# MSS_CTRL_MSS_CTRL_50D00000h register map
Vendor: Texas Instruments
Registers are 32-bit, read-only, reset values left out (the file's numbers can be read two ways) unless marked. A register's access mark holds for its fields unless they carry their own. Offsets are as the file gives them; [hi:lo] are bit positions; {n}, {i} and the like mark numbered series.

## MSS_CTRL (part 4 of 10)
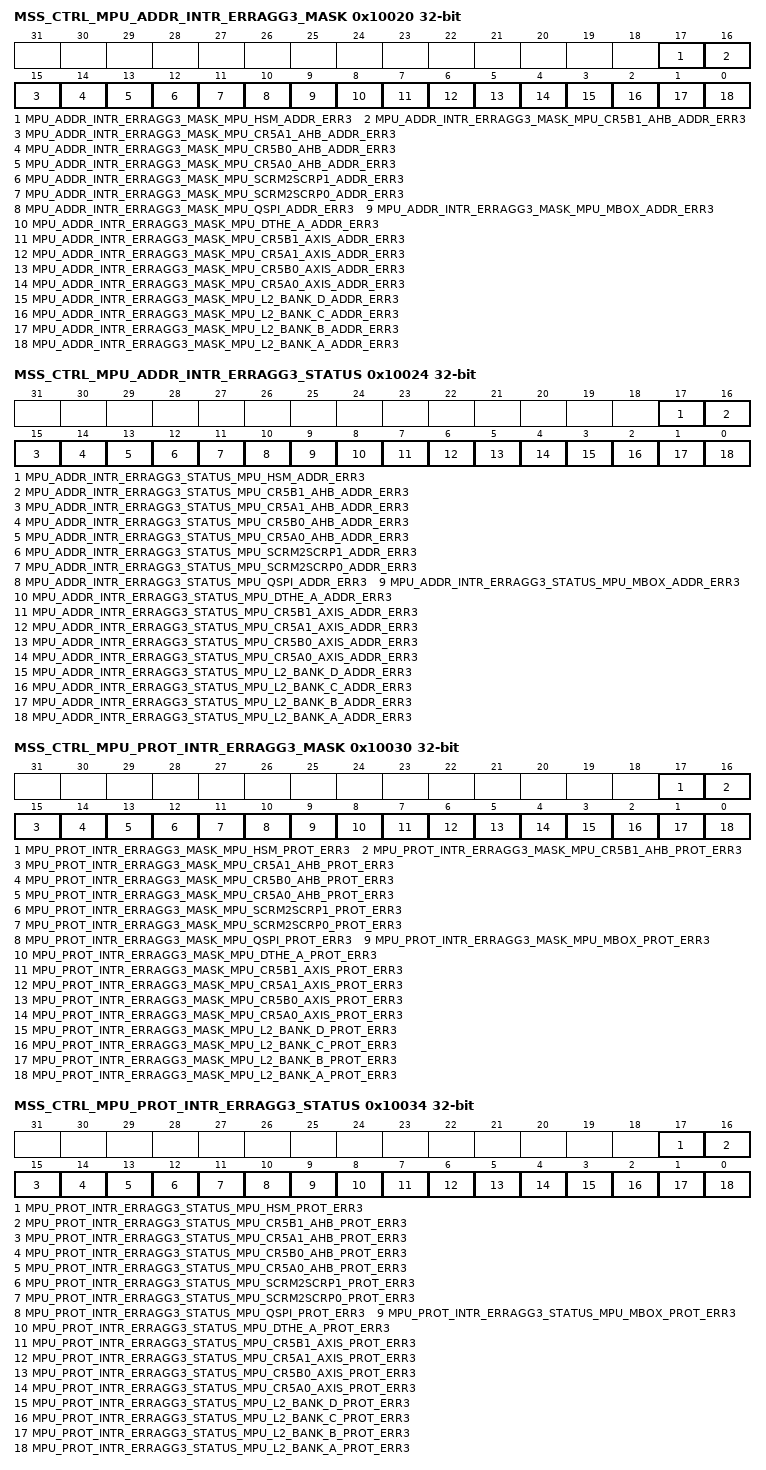
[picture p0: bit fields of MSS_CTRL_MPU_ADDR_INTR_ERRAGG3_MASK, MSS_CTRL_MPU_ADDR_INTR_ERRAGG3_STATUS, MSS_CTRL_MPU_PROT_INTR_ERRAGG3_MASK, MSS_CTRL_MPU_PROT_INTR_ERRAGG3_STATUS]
0x10020 MSS_CTRL_MPU_ADDR_INTR_ERRAGG3_MASK rw — This register Masks selected interrupt soures from generating MPU Address Error Interrupt to R5SS1 CORE1 .
  [17] MPU_ADDR_INTR_ERRAGG3_MASK_MPU_HSM_ADDR_ERR3 — Mask Error from MPU_ADDR_INTR to aggregated Error MPU_ADDR_INTR_ERRAGG1'b1 : Error is Masked1'b0 : Error is Unmasked
  [16] MPU_ADDR_INTR_ERRAGG3_MASK_MPU_CR5B1_AHB_ADDR_ERR3 — Mask Error from MPU_ADDR_INTR to aggregated Error MPU_ADDR_INTR_ERRAGG1'b1 : Error is Masked1'b0 : Error is Unmasked
  [15] MPU_ADDR_INTR_ERRAGG3_MASK_MPU_CR5A1_AHB_ADDR_ERR3 — Mask Error from MPU_ADDR_INTR to aggregated Error MPU_ADDR_INTR_ERRAGG1'b1 : Error is Masked1'b0 : Error is Unmasked
  [14] MPU_ADDR_INTR_ERRAGG3_MASK_MPU_CR5B0_AHB_ADDR_ERR3 — Mask Error from MPU_ADDR_INTR to aggregated Error MPU_ADDR_INTR_ERRAGG1'b1 : Error is Masked1'b0 : Error is Unmasked
  [13] MPU_ADDR_INTR_ERRAGG3_MASK_MPU_CR5A0_AHB_ADDR_ERR3 — Mask Error from MPU_ADDR_INTR to aggregated Error MPU_ADDR_INTR_ERRAGG1'b1 : Error is Masked1'b0 : Error is Unmasked
  [12] MPU_ADDR_INTR_ERRAGG3_MASK_MPU_SCRM2SCRP1_ADDR_ERR3 — Mask Error from MPU_ADDR_INTR to aggregated Error MPU_ADDR_INTR_ERRAGG1'b1 : Error is Masked1'b0 : Error is Unmasked
  [11] MPU_ADDR_INTR_ERRAGG3_MASK_MPU_SCRM2SCRP0_ADDR_ERR3 — Mask Error from MPU_ADDR_INTR to aggregated Error MPU_ADDR_INTR_ERRAGG1'b1 : Error is Masked1'b0 : Error is Unmasked
  [10] MPU_ADDR_INTR_ERRAGG3_MASK_MPU_QSPI_ADDR_ERR3 — Mask Error from MPU_ADDR_INTR to aggregated Error MPU_ADDR_INTR_ERRAGG1'b1 : Error is Masked1'b0 : Error is Unmasked
  [9] MPU_ADDR_INTR_ERRAGG3_MASK_MPU_MBOX_ADDR_ERR3 — Mask Error from MPU_ADDR_INTR to aggregated Error MPU_ADDR_INTR_ERRAGG1'b1 : Error is Masked1'b0 : Error is Unmasked
  [8] MPU_ADDR_INTR_ERRAGG3_MASK_MPU_DTHE_A_ADDR_ERR3 — Mask Error from MPU_ADDR_INTR to aggregated Error MPU_ADDR_INTR_ERRAGG1'b1 : Error is Masked1'b0 : Error is Unmasked
  [7] MPU_ADDR_INTR_ERRAGG3_MASK_MPU_CR5B1_AXIS_ADDR_ERR3 — Mask Error from MPU_ADDR_INTR to aggregated Error MPU_ADDR_INTR_ERRAGG1'b1 : Error is Masked1'b0 : Error is Unmasked
  [6] MPU_ADDR_INTR_ERRAGG3_MASK_MPU_CR5A1_AXIS_ADDR_ERR3 — Mask Error from MPU_ADDR_INTR to aggregated Error MPU_ADDR_INTR_ERRAGG1'b1 : Error is Masked1'b0 : Error is Unmasked
  [5] MPU_ADDR_INTR_ERRAGG3_MASK_MPU_CR5B0_AXIS_ADDR_ERR3 — Mask Error from MPU_ADDR_INTR to aggregated Error MPU_ADDR_INTR_ERRAGG1'b1 : Error is Masked1'b0 : Error is Unmasked
  [4] MPU_ADDR_INTR_ERRAGG3_MASK_MPU_CR5A0_AXIS_ADDR_ERR3 — Mask Error from MPU_ADDR_INTR to aggregated Error MPU_ADDR_INTR_ERRAGG1'b1 : Error is Masked1'b0 : Error is Unmasked
  [3] MPU_ADDR_INTR_ERRAGG3_MASK_MPU_L2_BANK_D_ADDR_ERR3 — Mask Error from MPU_ADDR_INTR to aggregated Error MPU_ADDR_INTR_ERRAGG1'b1 : Error is Masked1'b0 : Error is Unmasked
  [2] MPU_ADDR_INTR_ERRAGG3_MASK_MPU_L2_BANK_C_ADDR_ERR3 — Mask Error from MPU_ADDR_INTR to aggregated Error MPU_ADDR_INTR_ERRAGG1'b1 : Error is Masked1'b0 : Error is Unmasked
  [1] MPU_ADDR_INTR_ERRAGG3_MASK_MPU_L2_BANK_B_ADDR_ERR3 — Mask Error from MPU_ADDR_INTR to aggregated Error MPU_ADDR_INTR_ERRAGG1'b1 : Error is Masked1'b0 : Error is Unmasked
  [0] MPU_ADDR_INTR_ERRAGG3_MASK_MPU_L2_BANK_A_ADDR_ERR3 — Mask Error from MPU_ADDR_INTR to aggregated Error MPU_ADDR_INTR_ERRAGG1'b1 : Error is Masked1'b0 : Error is Unmasked
0x10024 MSS_CTRL_MPU_ADDR_INTR_ERRAGG3_STATUS rw — This register shows the Status of Unmasked MPU Address Errors to R5SS1 CORE1 .
  [17] MPU_ADDR_INTR_ERRAGG3_STATUS_MPU_HSM_ADDR_ERR3 — Status of Error from MPU_ADDR_INTR. Set only if Interupt is unmasked in MPU_ADDR_INTR_ERRAGG_MASKWrie 0x1 to clear this Error.
  [16] MPU_ADDR_INTR_ERRAGG3_STATUS_MPU_CR5B1_AHB_ADDR_ERR3 — Status of Error from MPU_ADDR_INTR. Set only if Interupt is unmasked in MPU_ADDR_INTR_ERRAGG_MASKWrie 0x1 to clear this Error.
  [15] MPU_ADDR_INTR_ERRAGG3_STATUS_MPU_CR5A1_AHB_ADDR_ERR3 — Status of Error from MPU_ADDR_INTR. Set only if Interupt is unmasked in MPU_ADDR_INTR_ERRAGG_MASKWrie 0x1 to clear this Error.
  [14] MPU_ADDR_INTR_ERRAGG3_STATUS_MPU_CR5B0_AHB_ADDR_ERR3 — Status of Error from MPU_ADDR_INTR. Set only if Interupt is unmasked in MPU_ADDR_INTR_ERRAGG_MASKWrie 0x1 to clear this Error.
  [13] MPU_ADDR_INTR_ERRAGG3_STATUS_MPU_CR5A0_AHB_ADDR_ERR3 — Status of Error from MPU_ADDR_INTR. Set only if Interupt is unmasked in MPU_ADDR_INTR_ERRAGG_MASKWrie 0x1 to clear this Error.
  [12] MPU_ADDR_INTR_ERRAGG3_STATUS_MPU_SCRM2SCRP1_ADDR_ERR3 — Status of Error from MPU_ADDR_INTR. Set only if Interupt is unmasked in MPU_ADDR_INTR_ERRAGG_MASKWrie 0x1 to clear this Error.
  [11] MPU_ADDR_INTR_ERRAGG3_STATUS_MPU_SCRM2SCRP0_ADDR_ERR3 — Status of Error from MPU_ADDR_INTR. Set only if Interupt is unmasked in MPU_ADDR_INTR_ERRAGG_MASKWrie 0x1 to clear this Error.
  [10] MPU_ADDR_INTR_ERRAGG3_STATUS_MPU_QSPI_ADDR_ERR3 — Status of Error from MPU_ADDR_INTR. Set only if Interupt is unmasked in MPU_ADDR_INTR_ERRAGG_MASKWrie 0x1 to clear this Error.
  [9] MPU_ADDR_INTR_ERRAGG3_STATUS_MPU_MBOX_ADDR_ERR3 — Status of Error from MPU_ADDR_INTR. Set only if Interupt is unmasked in MPU_ADDR_INTR_ERRAGG_MASKWrie 0x1 to clear this Error.
  [8] MPU_ADDR_INTR_ERRAGG3_STATUS_MPU_DTHE_A_ADDR_ERR3 — Status of Error from MPU_ADDR_INTR. Set only if Interupt is unmasked in MPU_ADDR_INTR_ERRAGG_MASKWrie 0x1 to clear this Error.
  [7] MPU_ADDR_INTR_ERRAGG3_STATUS_MPU_CR5B1_AXIS_ADDR_ERR3 — Status of Error from MPU_ADDR_INTR. Set only if Interupt is unmasked in MPU_ADDR_INTR_ERRAGG_MASKWrie 0x1 to clear this Error.
  [6] MPU_ADDR_INTR_ERRAGG3_STATUS_MPU_CR5A1_AXIS_ADDR_ERR3 — Status of Error from MPU_ADDR_INTR. Set only if Interupt is unmasked in MPU_ADDR_INTR_ERRAGG_MASKWrie 0x1 to clear this Error.
  [5] MPU_ADDR_INTR_ERRAGG3_STATUS_MPU_CR5B0_AXIS_ADDR_ERR3 — Status of Error from MPU_ADDR_INTR. Set only if Interupt is unmasked in MPU_ADDR_INTR_ERRAGG_MASKWrie 0x1 to clear this Error.
  [4] MPU_ADDR_INTR_ERRAGG3_STATUS_MPU_CR5A0_AXIS_ADDR_ERR3 — Status of Error from MPU_ADDR_INTR. Set only if Interupt is unmasked in MPU_ADDR_INTR_ERRAGG_MASKWrie 0x1 to clear this Error.
  [3] MPU_ADDR_INTR_ERRAGG3_STATUS_MPU_L2_BANK_D_ADDR_ERR3 — Status of Error from MPU_ADDR_INTR. Set only if Interupt is unmasked in MPU_ADDR_INTR_ERRAGG_MASKWrie 0x1 to clear this Error.
  [2] MPU_ADDR_INTR_ERRAGG3_STATUS_MPU_L2_BANK_C_ADDR_ERR3 — Status of Error from MPU_ADDR_INTR. Set only if Interupt is unmasked in MPU_ADDR_INTR_ERRAGG_MASKWrie 0x1 to clear this Error.
  [1] MPU_ADDR_INTR_ERRAGG3_STATUS_MPU_L2_BANK_B_ADDR_ERR3 — Status of Error from MPU_ADDR_INTR. Set only if Interupt is unmasked in MPU_ADDR_INTR_ERRAGG_MASKWrie 0x1 to clear this Error.
  [0] MPU_ADDR_INTR_ERRAGG3_STATUS_MPU_L2_BANK_A_ADDR_ERR3 — Status of Error from MPU_ADDR_INTR. Set only if Interupt is unmasked in MPU_ADDR_INTR_ERRAGG_MASKWrie 0x1 to clear this Error.
0x10030 MSS_CTRL_MPU_PROT_INTR_ERRAGG3_MASK rw — This register Masks selected interrupt soures from generating MPU Protection Error Interrupt to R5SS1 CORE1 .
  [17] MPU_PROT_INTR_ERRAGG3_MASK_MPU_HSM_PROT_ERR3 — Mask Error from MPU_PROT_INTR to aggregated Error MPU_PROT_INTR_ERRAGG1'b1 : Error is Masked1'b0 : Error is Unmasked
  [16] MPU_PROT_INTR_ERRAGG3_MASK_MPU_CR5B1_AHB_PROT_ERR3 — Mask Error from MPU_PROT_INTR to aggregated Error MPU_PROT_INTR_ERRAGG1'b1 : Error is Masked1'b0 : Error is Unmasked
  [15] MPU_PROT_INTR_ERRAGG3_MASK_MPU_CR5A1_AHB_PROT_ERR3 — Mask Error from MPU_PROT_INTR to aggregated Error MPU_PROT_INTR_ERRAGG1'b1 : Error is Masked1'b0 : Error is Unmasked
  [14] MPU_PROT_INTR_ERRAGG3_MASK_MPU_CR5B0_AHB_PROT_ERR3 — Mask Error from MPU_PROT_INTR to aggregated Error MPU_PROT_INTR_ERRAGG1'b1 : Error is Masked1'b0 : Error is Unmasked
  [13] MPU_PROT_INTR_ERRAGG3_MASK_MPU_CR5A0_AHB_PROT_ERR3 — Mask Error from MPU_PROT_INTR to aggregated Error MPU_PROT_INTR_ERRAGG1'b1 : Error is Masked1'b0 : Error is Unmasked
  [12] MPU_PROT_INTR_ERRAGG3_MASK_MPU_SCRM2SCRP1_PROT_ERR3 — Mask Error from MPU_PROT_INTR to aggregated Error MPU_PROT_INTR_ERRAGG1'b1 : Error is Masked1'b0 : Error is Unmasked
  [11] MPU_PROT_INTR_ERRAGG3_MASK_MPU_SCRM2SCRP0_PROT_ERR3 — Mask Error from MPU_PROT_INTR to aggregated Error MPU_PROT_INTR_ERRAGG1'b1 : Error is Masked1'b0 : Error is Unmasked
  [10] MPU_PROT_INTR_ERRAGG3_MASK_MPU_QSPI_PROT_ERR3 — Mask Error from MPU_PROT_INTR to aggregated Error MPU_PROT_INTR_ERRAGG1'b1 : Error is Masked1'b0 : Error is Unmasked
  [9] MPU_PROT_INTR_ERRAGG3_MASK_MPU_MBOX_PROT_ERR3 — Mask Error from MPU_PROT_INTR to aggregated Error MPU_PROT_INTR_ERRAGG1'b1 : Error is Masked1'b0 : Error is Unmasked
  [8] MPU_PROT_INTR_ERRAGG3_MASK_MPU_DTHE_A_PROT_ERR3 — Mask Error from MPU_PROT_INTR to aggregated Error MPU_PROT_INTR_ERRAGG1'b1 : Error is Masked1'b0 : Error is Unmasked
  [7] MPU_PROT_INTR_ERRAGG3_MASK_MPU_CR5B1_AXIS_PROT_ERR3 — Mask Error from MPU_PROT_INTR to aggregated Error MPU_PROT_INTR_ERRAGG1'b1 : Error is Masked1'b0 : Error is Unmasked
  [6] MPU_PROT_INTR_ERRAGG3_MASK_MPU_CR5A1_AXIS_PROT_ERR3 — Mask Error from MPU_PROT_INTR to aggregated Error MPU_PROT_INTR_ERRAGG1'b1 : Error is Masked1'b0 : Error is Unmasked
  [5] MPU_PROT_INTR_ERRAGG3_MASK_MPU_CR5B0_AXIS_PROT_ERR3 — Mask Error from MPU_PROT_INTR to aggregated Error MPU_PROT_INTR_ERRAGG1'b1 : Error is Masked1'b0 : Error is Unmasked
  [4] MPU_PROT_INTR_ERRAGG3_MASK_MPU_CR5A0_AXIS_PROT_ERR3 — Mask Error from MPU_PROT_INTR to aggregated Error MPU_PROT_INTR_ERRAGG1'b1 : Error is Masked1'b0 : Error is Unmasked
  [3] MPU_PROT_INTR_ERRAGG3_MASK_MPU_L2_BANK_D_PROT_ERR3 — Mask Error from MPU_PROT_INTR to aggregated Error MPU_PROT_INTR_ERRAGG1'b1 : Error is Masked1'b0 : Error is Unmasked
  [2] MPU_PROT_INTR_ERRAGG3_MASK_MPU_L2_BANK_C_PROT_ERR3 — Mask Error from MPU_PROT_INTR to aggregated Error MPU_PROT_INTR_ERRAGG1'b1 : Error is Masked1'b0 : Error is Unmasked
  [1] MPU_PROT_INTR_ERRAGG3_MASK_MPU_L2_BANK_B_PROT_ERR3 — Mask Error from MPU_PROT_INTR to aggregated Error MPU_PROT_INTR_ERRAGG1'b1 : Error is Masked1'b0 : Error is Unmasked
  [0] MPU_PROT_INTR_ERRAGG3_MASK_MPU_L2_BANK_A_PROT_ERR3 — Mask Error from MPU_PROT_INTR to aggregated Error MPU_PROT_INTR_ERRAGG1'b1 : Error is Masked1'b0 : Error is Unmasked
0x10034 MSS_CTRL_MPU_PROT_INTR_ERRAGG3_STATUS rw — This register shows the Status of Unmasked MPU Protection Errors to R5SS1 CORE1 .
  [17] MPU_PROT_INTR_ERRAGG3_STATUS_MPU_HSM_PROT_ERR3 — Status of Error from MPU_PROT_INTR. Set only if Interupt is unmasked in MPU_PROT_INTR_ERRAGG_MASKWrie 0x1 to clear this Error.
  [16] MPU_PROT_INTR_ERRAGG3_STATUS_MPU_CR5B1_AHB_PROT_ERR3 — Status of Error from MPU_PROT_INTR. Set only if Interupt is unmasked in MPU_PROT_INTR_ERRAGG_MASKWrie 0x1 to clear this Error.
  [15] MPU_PROT_INTR_ERRAGG3_STATUS_MPU_CR5A1_AHB_PROT_ERR3 — Status of Error from MPU_PROT_INTR. Set only if Interupt is unmasked in MPU_PROT_INTR_ERRAGG_MASKWrie 0x1 to clear this Error.
  [14] MPU_PROT_INTR_ERRAGG3_STATUS_MPU_CR5B0_AHB_PROT_ERR3 — Status of Error from MPU_PROT_INTR. Set only if Interupt is unmasked in MPU_PROT_INTR_ERRAGG_MASKWrie 0x1 to clear this Error.
  [13] MPU_PROT_INTR_ERRAGG3_STATUS_MPU_CR5A0_AHB_PROT_ERR3 — Status of Error from MPU_PROT_INTR. Set only if Interupt is unmasked in MPU_PROT_INTR_ERRAGG_MASKWrie 0x1 to clear this Error.
  [12] MPU_PROT_INTR_ERRAGG3_STATUS_MPU_SCRM2SCRP1_PROT_ERR3 — Status of Error from MPU_PROT_INTR. Set only if Interupt is unmasked in MPU_PROT_INTR_ERRAGG_MASKWrie 0x1 to clear this Error.
  [11] MPU_PROT_INTR_ERRAGG3_STATUS_MPU_SCRM2SCRP0_PROT_ERR3 — Status of Error from MPU_PROT_INTR. Set only if Interupt is unmasked in MPU_PROT_INTR_ERRAGG_MASKWrie 0x1 to clear this Error.
  [10] MPU_PROT_INTR_ERRAGG3_STATUS_MPU_QSPI_PROT_ERR3 — Status of Error from MPU_PROT_INTR. Set only if Interupt is unmasked in MPU_PROT_INTR_ERRAGG_MASKWrie 0x1 to clear this Error.
  [9] MPU_PROT_INTR_ERRAGG3_STATUS_MPU_MBOX_PROT_ERR3 — Status of Error from MPU_PROT_INTR. Set only if Interupt is unmasked in MPU_PROT_INTR_ERRAGG_MASKWrie 0x1 to clear this Error.
  [8] MPU_PROT_INTR_ERRAGG3_STATUS_MPU_DTHE_A_PROT_ERR3 — Status of Error from MPU_PROT_INTR. Set only if Interupt is unmasked in MPU_PROT_INTR_ERRAGG_MASKWrie 0x1 to clear this Error.
  [7] MPU_PROT_INTR_ERRAGG3_STATUS_MPU_CR5B1_AXIS_PROT_ERR3 — Status of Error from MPU_PROT_INTR. Set only if Interupt is unmasked in MPU_PROT_INTR_ERRAGG_MASKWrie 0x1 to clear this Error.
  [6] MPU_PROT_INTR_ERRAGG3_STATUS_MPU_CR5A1_AXIS_PROT_ERR3 — Status of Error from MPU_PROT_INTR. Set only if Interupt is unmasked in MPU_PROT_INTR_ERRAGG_MASKWrie 0x1 to clear this Error.
  [5] MPU_PROT_INTR_ERRAGG3_STATUS_MPU_CR5B0_AXIS_PROT_ERR3 — Status of Error from MPU_PROT_INTR. Set only if Interupt is unmasked in MPU_PROT_INTR_ERRAGG_MASKWrie 0x1 to clear this Error.
  [4] MPU_PROT_INTR_ERRAGG3_STATUS_MPU_CR5A0_AXIS_PROT_ERR3 — Status of Error from MPU_PROT_INTR. Set only if Interupt is unmasked in MPU_PROT_INTR_ERRAGG_MASKWrie 0x1 to clear this Error.
  [3] MPU_PROT_INTR_ERRAGG3_STATUS_MPU_L2_BANK_D_PROT_ERR3 — Status of Error from MPU_PROT_INTR. Set only if Interupt is unmasked in MPU_PROT_INTR_ERRAGG_MASKWrie 0x1 to clear this Error.
  [2] MPU_PROT_INTR_ERRAGG3_STATUS_MPU_L2_BANK_C_PROT_ERR3 — Status of Error from MPU_PROT_INTR. Set only if Interupt is unmasked in MPU_PROT_INTR_ERRAGG_MASKWrie 0x1 to clear this Error.
  [1] MPU_PROT_INTR_ERRAGG3_STATUS_MPU_L2_BANK_B_PROT_ERR3 — Status of Error from MPU_PROT_INTR. Set only if Interupt is unmasked in MPU_PROT_INTR_ERRAGG_MASKWrie 0x1 to clear this Error.
  [0] MPU_PROT_INTR_ERRAGG3_STATUS_MPU_L2_BANK_A_PROT_ERR3 — Status of Error from MPU_PROT_INTR. Set only if Interupt is unmasked in MPU_PROT_INTR_ERRAGG_MASKWrie 0x1 to clear this Error.
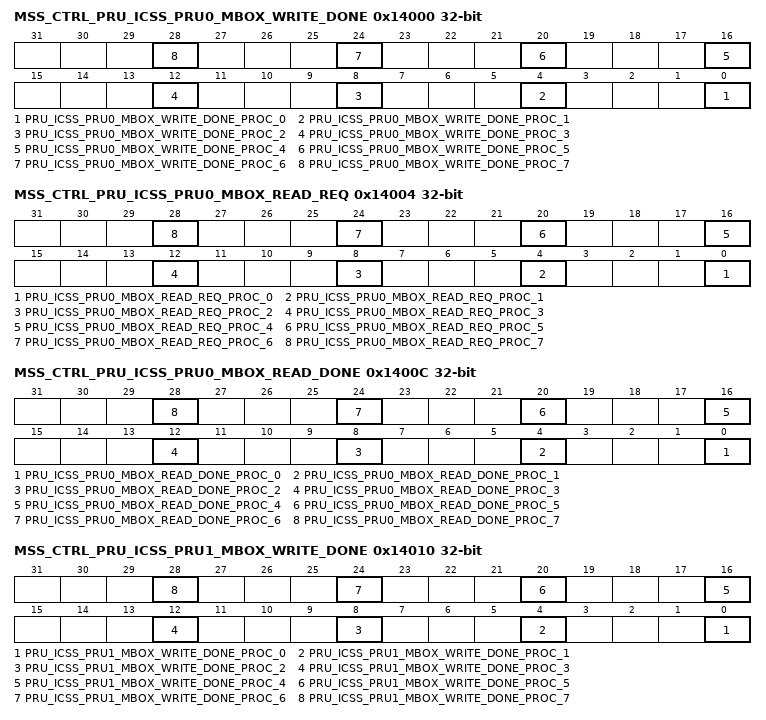
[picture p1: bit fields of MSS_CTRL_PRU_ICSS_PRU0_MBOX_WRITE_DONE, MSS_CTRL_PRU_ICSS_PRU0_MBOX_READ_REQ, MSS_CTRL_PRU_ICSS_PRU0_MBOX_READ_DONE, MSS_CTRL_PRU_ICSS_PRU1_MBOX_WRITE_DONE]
0x14000 MSS_CTRL_PRU_ICSS_PRU0_MBOX_WRITE_DONE rw — This register is used by ICSSM PRU0 to generate Mailbox interrupt to Recipent CPU.
  [4n] PRU_ICSS_PRU0_MBOX_WRITE_DONE_PROC_{n} (n=0..7) — Write pulse bit field:This register should be written once finishing Writing into the mailbox memory of processor {n}
0x14004 MSS_CTRL_PRU_ICSS_PRU0_MBOX_READ_REQ rw — This register is used by ICSSM PRU0 to know the Sender of Mailbox Interrupt as well as clear it.
  [4n] PRU_ICSS_PRU0_MBOX_READ_REQ_PROC_{n} (n=0..7) — This is request from processor {n} to corresponding ICSSM_PRU. Requesting it to read from mailbox.
0x14008 MSS_CTRL_PRU_ICSS_PRU0_MBOX_READ_DONE_ACK rw — This register is used by ICSSM PRU0 to generate Mailbox Read acknowledgement to the Sender CPU.
  [7:0] PRU_ICSS_PRU0_MBOX_READ_DONE_ACK_PROC — Write pulse bit field:For bits 0 to7:Wrting1'b1 : Generates pulse interrupt to corresponding proc from ICSSM_PRU0.For bits 8 to15:Wrting1'b1 : Generates pulse interrupt to corresponding proc from ICSSM_PRU1.
0x1400C MSS_CTRL_PRU_ICSS_PRU0_MBOX_READ_DONE rw — This register is used by ICSSM PRU0 to know that the Receiver CPU has read the Mailbox and Acked. It is also used to clear the Read Done Interrupt.
  [4n] PRU_ICSS_PRU0_MBOX_READ_DONE_PROC_{n} (n=0..7) — This register should be written once finishing Reading from corresponding proc{n}'s mailbox written by ICSSM_PRU
0x14010 MSS_CTRL_PRU_ICSS_PRU1_MBOX_WRITE_DONE rw — This register is used by ICSSM PRU1 to generate Mailbox interrupt to Recipent CPU.
  [4n] PRU_ICSS_PRU1_MBOX_WRITE_DONE_PROC_{n} (n=0..7) — Write pulse bit field:This register should be written once finishing Writing into the mailbox memory of processor {n}
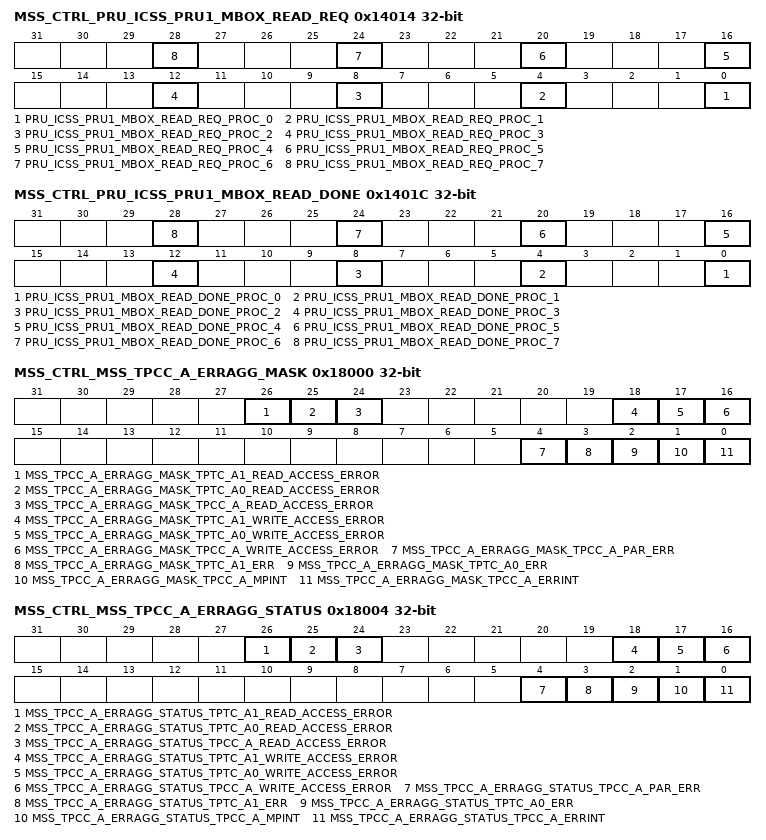
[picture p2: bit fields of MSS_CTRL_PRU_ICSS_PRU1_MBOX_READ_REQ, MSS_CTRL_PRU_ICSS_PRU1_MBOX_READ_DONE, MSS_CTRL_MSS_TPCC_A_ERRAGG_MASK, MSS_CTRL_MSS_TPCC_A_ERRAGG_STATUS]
0x14014 MSS_CTRL_PRU_ICSS_PRU1_MBOX_READ_REQ rw — This register is used by ICSSM PRU1 to know the Sender of Mailbox Interrupt as well as clear it.
  [4n] PRU_ICSS_PRU1_MBOX_READ_REQ_PROC_{n} (n=0..7) — This is request from processor {n} to corresponding ICSSM_PRU. Requesting it to read from mailbox.
0x14018 MSS_CTRL_PRU_ICSS_PRU1_MBOX_READ_DONE_ACK rw — This register is used by ICSSM PRU1 to generate Mailbox Read acknowledgement to the Sender CPU.
  [7:0] PRU_ICSS_PRU1_MBOX_READ_DONE_ACK_PROC — Write pulse bit field:For bits 0 to7:Wrting1'b1 : Generates pulse interrupt to corresponding proc from ICSSM_PRU0.For bits 8 to15:Wrting1'b1 : Generates pulse interrupt to corresponding proc from ICSSM_PRU1.
0x1401C MSS_CTRL_PRU_ICSS_PRU1_MBOX_READ_DONE rw — This register is used by ICSSM PRU1 to know that the Receiver CPU has read the Mailbox and Acked. It is also used to clear the Read Done Interrupt.
  [4n] PRU_ICSS_PRU1_MBOX_READ_DONE_PROC_{n} (n=0..7) — This register should be written once finishing Reading from corresponding proc{n}'s mailbox written by ICSSM_PRU
0x18000 MSS_CTRL_MSS_TPCC_A_ERRAGG_MASK rw — This register Masks selected interrupt soures from generating the Aggregated TPCC0 Error Interrupt.
  [26] MSS_TPCC_A_ERRAGG_MASK_TPTC_A1_READ_ACCESS_ERROR — Mask Error from MSS_TPTC_A1 to aggregated Error MSS_TPCC_A_ERRAGG1'b1 : Error is Masked1'b0 : Error is Unmasked
  [25] MSS_TPCC_A_ERRAGG_MASK_TPTC_A0_READ_ACCESS_ERROR — Mask Error from MSS_TPTC_A0 to aggregated Error MSS_TPCC_A_ERRAGG1'b1 : Error is Masked1'b0 : Error is Unmasked
  [24] MSS_TPCC_A_ERRAGG_MASK_TPCC_A_READ_ACCESS_ERROR — Mask Error from MSS_TPCC_A to aggregated Error MSS_TPCC_A_ERRAGG1'b1 : Error is Masked1'b0 : Error is Unmasked
  [18] MSS_TPCC_A_ERRAGG_MASK_TPTC_A1_WRITE_ACCESS_ERROR — Mask Error from MSS_TPTC_A1 to aggregated Error MSS_TPCC_A_ERRAGG1'b1 : Error is Masked1'b0 : Error is Unmasked
  [17] MSS_TPCC_A_ERRAGG_MASK_TPTC_A0_WRITE_ACCESS_ERROR — Mask Error from MSS_TPTC_A0 to aggregated Error MSS_TPCC_A_ERRAGG1'b1 : Error is Masked1'b0 : Error is Unmasked
  [16] MSS_TPCC_A_ERRAGG_MASK_TPCC_A_WRITE_ACCESS_ERROR — Mask Error from MSS_TPCC_A to aggregated Error MSS_TPCC_A_ERRAGG1'b1 : Error is Masked1'b0 : Error is Unmasked
  [4] MSS_TPCC_A_ERRAGG_MASK_TPCC_A_PAR_ERR — Mask Error from MSS_TPCC_A to aggregated Error MSS_TPCC_A_ERRAGG1'b1 : Error is Masked1'b0 : Error is Unmasked
  [3] MSS_TPCC_A_ERRAGG_MASK_TPTC_A1_ERR — Mask Error from MSS_TPTC_A1 to aggregated Error MSS_TPCC_A_ERRAGG1'b1 : Error is Masked1'b0 : Error is Unmasked
  [2] MSS_TPCC_A_ERRAGG_MASK_TPTC_A0_ERR — Mask Error from MSS_TPTC_A0 to aggregated Error MSS_TPCC_A_ERRAGG1'b1 : Error is Masked1'b0 : Error is Unmasked
  [1] MSS_TPCC_A_ERRAGG_MASK_TPCC_A_MPINT — Mask Error from MSS_TPCC_A to aggregated Error MSS_TPCC_A_ERRAGG1'b1 : Error is Masked1'b0 : Error is Unmasked
  [0] MSS_TPCC_A_ERRAGG_MASK_TPCC_A_ERRINT — Mask Error from MSS_TPCC_A to aggregated Error MSS_TPCC_A_ERRAGG1'b1 : Error is Masked1'b0 : Error is Unmasked
0x18004 MSS_CTRL_MSS_TPCC_A_ERRAGG_STATUS rw — This register shows the Status of Unmasked Errors from TPCC0.
  [26] MSS_TPCC_A_ERRAGG_STATUS_TPTC_A1_READ_ACCESS_ERROR — Status of Error from MSS_TPTC_A1. Set only if Interupt is unmasked in MSS_TPCC_A_ERRAGG_MASKWrie 0x1 to clear this Error.
  [25] MSS_TPCC_A_ERRAGG_STATUS_TPTC_A0_READ_ACCESS_ERROR — Status of Error from MSS_TPTC_A0. Set only if Interupt is unmasked in MSS_TPCC_A_ERRAGG_MASKWrie 0x1 to clear this Error.
  [24] MSS_TPCC_A_ERRAGG_STATUS_TPCC_A_READ_ACCESS_ERROR — Status of Error from MSS_TPCC_A. Set only if Interupt is unmasked in MSS_TPCC_A_ERRAGG_MASKWrie 0x1 to clear this Error.
  [18] MSS_TPCC_A_ERRAGG_STATUS_TPTC_A1_WRITE_ACCESS_ERROR — Status of Error from MSS_TPTC_A1. Set only if Interupt is unmasked in MSS_TPCC_A_ERRAGG_MASKWrie 0x1 to clear this Error.
  [17] MSS_TPCC_A_ERRAGG_STATUS_TPTC_A0_WRITE_ACCESS_ERROR — Status of Error from MSS_TPTC_A0. Set only if Interupt is unmasked in MSS_TPCC_A_ERRAGG_MASKWrie 0x1 to clear this Error.
  [16] MSS_TPCC_A_ERRAGG_STATUS_TPCC_A_WRITE_ACCESS_ERROR — Status of Error from MSS_TPCC_A. Set only if Interupt is unmasked in MSS_TPCC_A_ERRAGG_MASKWrie 0x1 to clear this Error.
  [4] MSS_TPCC_A_ERRAGG_STATUS_TPCC_A_PAR_ERR — Status of Error from MSS_TPCC_A. Set only if Interupt is unmasked in MSS_TPCC_A_ERRAGG_MASKWrie 0x1 to clear this Error.
  [3] MSS_TPCC_A_ERRAGG_STATUS_TPTC_A1_ERR — Status of Error from MSS_TPTC_A1. Set only if Interupt is unmasked in MSS_TPCC_A_ERRAGG_MASKWrie 0x1 to clear this Error.
  [2] MSS_TPCC_A_ERRAGG_STATUS_TPTC_A0_ERR — Status of Error from MSS_TPTC_A0. Set only if Interupt is unmasked in MSS_TPCC_A_ERRAGG_MASKWrie 0x1 to clear this Error.
  [1] MSS_TPCC_A_ERRAGG_STATUS_TPCC_A_MPINT — Status of Error from MSS_TPCC_A. Set only if Interupt is unmasked in MSS_TPCC_A_ERRAGG_MASKWrie 0x1 to clear this Error.
  [0] MSS_TPCC_A_ERRAGG_STATUS_TPCC_A_ERRINT — Status of Error from MSS_TPCC_A. Set only if Interupt is unmasked in MSS_TPCC_A_ERRAGG_MASKWrie 0x1 to clear this Error.
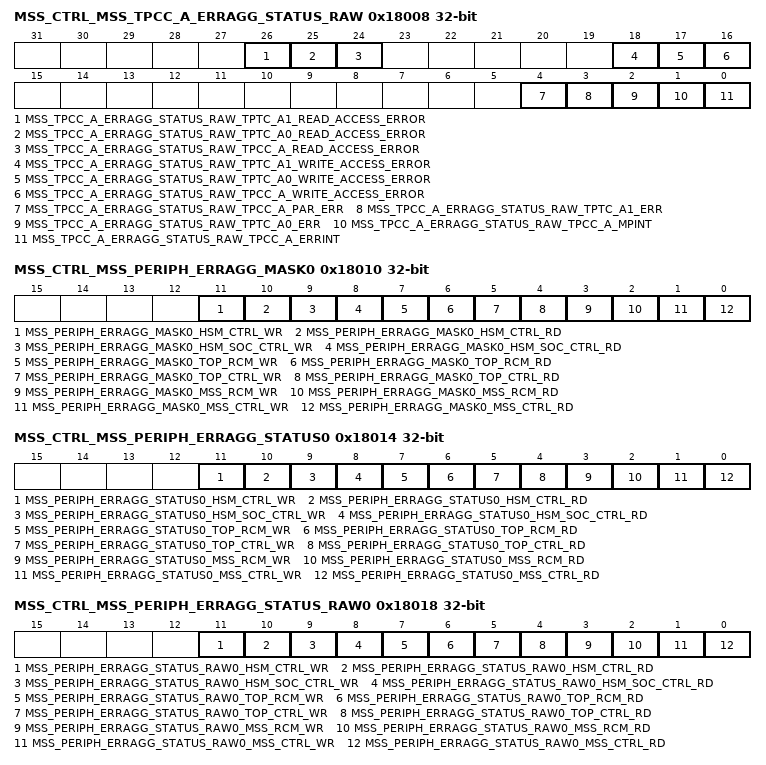
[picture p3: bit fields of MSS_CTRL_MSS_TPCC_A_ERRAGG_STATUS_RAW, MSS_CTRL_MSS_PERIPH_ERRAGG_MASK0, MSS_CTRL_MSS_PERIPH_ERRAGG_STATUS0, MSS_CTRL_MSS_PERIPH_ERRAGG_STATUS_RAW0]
0x18008 MSS_CTRL_MSS_TPCC_A_ERRAGG_STATUS_RAW rw — This register shows the Status of all Errors from TPCC0.
  [26] MSS_TPCC_A_ERRAGG_STATUS_RAW_TPTC_A1_READ_ACCESS_ERROR — Raw Status of Error from MSS_TPTC_A1. Set irrespective if the Interupt is masked or unmasked in MSS_TPCC_A_ERRAGG_MASK
  [25] MSS_TPCC_A_ERRAGG_STATUS_RAW_TPTC_A0_READ_ACCESS_ERROR — Raw Status of Error from MSS_TPTC_A0. Set irrespective if the Interupt is masked or unmasked in MSS_TPCC_A_ERRAGG_MASK
  [24] MSS_TPCC_A_ERRAGG_STATUS_RAW_TPCC_A_READ_ACCESS_ERROR — Raw Status of Error from MSS_TPCC_A. Set irrespective if the Interupt is masked or unmasked in MSS_TPCC_A_ERRAGG_MASK
  [18] MSS_TPCC_A_ERRAGG_STATUS_RAW_TPTC_A1_WRITE_ACCESS_ERROR — Raw Status of Error from MSS_TPTC_A1. Set irrespective if the Interupt is masked or unmasked in MSS_TPCC_A_ERRAGG_MASK
  [17] MSS_TPCC_A_ERRAGG_STATUS_RAW_TPTC_A0_WRITE_ACCESS_ERROR — Raw Status of Error from MSS_TPTC_A0. Set irrespective if the Interupt is masked or unmasked in MSS_TPCC_A_ERRAGG_MASK
  [16] MSS_TPCC_A_ERRAGG_STATUS_RAW_TPCC_A_WRITE_ACCESS_ERROR — Raw Status of Error from MSS_TPCC_A. Set irrespective if the Interupt is masked or unmasked in MSS_TPCC_A_ERRAGG_MASK
  [4] MSS_TPCC_A_ERRAGG_STATUS_RAW_TPCC_A_PAR_ERR — Raw Status of Error from MSS_TPCC_A. Set irrespective if the Interupt is masked or unmasked in MSS_TPCC_A_ERRAGG_MASK
  [3] MSS_TPCC_A_ERRAGG_STATUS_RAW_TPTC_A1_ERR — Raw Status of Error from MSS_TPTC_A1. Set irrespective if the Interupt is masked or unmasked in MSS_TPCC_A_ERRAGG_MASK
  [2] MSS_TPCC_A_ERRAGG_STATUS_RAW_TPTC_A0_ERR — Raw Status of Error from MSS_TPTC_A0. Set irrespective if the Interupt is masked or unmasked in MSS_TPCC_A_ERRAGG_MASK
  [1] MSS_TPCC_A_ERRAGG_STATUS_RAW_TPCC_A_MPINT — Raw Status of Error from MSS_TPCC_A. Set irrespective if the Interupt is masked or unmasked in MSS_TPCC_A_ERRAGG_MASK
  [0] MSS_TPCC_A_ERRAGG_STATUS_RAW_TPCC_A_ERRINT — Raw Status of Error from MSS_TPCC_A. Set irrespective if the Interupt is masked or unmasked in MSS_TPCC_A_ERRAGG_MASK
0x18010 MSS_CTRL_MSS_PERIPH_ERRAGG_MASK0 rw — This register Masks selected interrupt soures from generating the Aggregated MMR Access Error Interrupt.
  [11] MSS_PERIPH_ERRAGG_MASK0_HSM_CTRL_WR — Mask Interrupt from HSM_CTRL to aggregated Interrupt MSS_PERIPH_ACCESS_ERRAGG1'b1 : Interrupt is Masked1'b0 : Interrupt is Unmasked
  [10] MSS_PERIPH_ERRAGG_MASK0_HSM_CTRL_RD — Mask Interrupt from HSM_CTRL to aggregated Interrupt MSS_PERIPH_ACCESS_ERRAGG1'b1 : Interrupt is Masked1'b0 : Interrupt is Unmasked
  [9] MSS_PERIPH_ERRAGG_MASK0_HSM_SOC_CTRL_WR — Mask Interrupt from HSM_SOC_CTRL to aggregated Interrupt MSS_PERIPH_ACCESS_ERRAGG1'b1 : Interrupt is Masked1'b0 : Interrupt is Unmasked
  [8] MSS_PERIPH_ERRAGG_MASK0_HSM_SOC_CTRL_RD — Mask Interrupt from HSM_SOC_CTRL to aggregated Interrupt MSS_PERIPH_ACCESS_ERRAGG1'b1 : Interrupt is Masked1'b0 : Interrupt is Unmasked
  [7] MSS_PERIPH_ERRAGG_MASK0_TOP_RCM_WR — Mask Interrupt from TOP_RCM to aggregated Interrupt MSS_PERIPH_ACCESS_ERRAGG1'b1 : Interrupt is Masked1'b0 : Interrupt is Unmasked
  [6] MSS_PERIPH_ERRAGG_MASK0_TOP_RCM_RD — Mask Interrupt from TOP_RCM to aggregated Interrupt MSS_PERIPH_ACCESS_ERRAGG1'b1 : Interrupt is Masked1'b0 : Interrupt is Unmasked
  [5] MSS_PERIPH_ERRAGG_MASK0_TOP_CTRL_WR — Mask Interrupt from TOP_CTRL to aggregated Interrupt MSS_PERIPH_ACCESS_ERRAGG1'b1 : Interrupt is Masked1'b0 : Interrupt is Unmasked
  [4] MSS_PERIPH_ERRAGG_MASK0_TOP_CTRL_RD — Mask Interrupt from TOP_CTRL to aggregated Interrupt MSS_PERIPH_ACCESS_ERRAGG1'b1 : Interrupt is Masked1'b0 : Interrupt is Unmasked
  [3] MSS_PERIPH_ERRAGG_MASK0_MSS_RCM_WR — Mask Interrupt from MSS_RCM to aggregated Interrupt MSS_PERIPH_ACCESS_ERRAGG1'b1 : Interrupt is Masked1'b0 : Interrupt is Unmasked
  [2] MSS_PERIPH_ERRAGG_MASK0_MSS_RCM_RD — Mask Interrupt from MSS_RCM to aggregated Interrupt MSS_PERIPH_ACCESS_ERRAGG1'b1 : Interrupt is Masked1'b0 : Interrupt is Unmasked
  [1] MSS_PERIPH_ERRAGG_MASK0_MSS_CTRL_WR — Mask Interrupt from MSS_CTRL to aggregated Interrupt MSS_PERIPH_ACCESS_ERRAGG1'b1 : Interrupt is Masked1'b0 : Interrupt is Unmasked
  [0] MSS_PERIPH_ERRAGG_MASK0_MSS_CTRL_RD — Mask Interrupt from MSS_CTRL to aggregated Interrupt MSS_PERIPH_ACCESS_ERRAGG1'b1 : Interrupt is Masked1'b0 : Interrupt is Unmasked
0x18014 MSS_CTRL_MSS_PERIPH_ERRAGG_STATUS0 rw — This register shows the Status of Unmasked MMR Access Errors.
  [11] MSS_PERIPH_ERRAGG_STATUS0_HSM_CTRL_WR — Status of Interrupt from HSM_CTRLSet only if Interupt is unmasked in MSS_PERIPH_ERRAGG_MASK0Wrie 0x1 to clear this interrupt.
  [10] MSS_PERIPH_ERRAGG_STATUS0_HSM_CTRL_RD — Status of Interrupt from HSM_CTRLSet only if Interupt is unmasked in MSS_PERIPH_ERRAGG_MASK0Wrie 0x1 to clear this interrupt.
  [9] MSS_PERIPH_ERRAGG_STATUS0_HSM_SOC_CTRL_WR — Status of Interrupt from HSM_SOC_CTRLSet only if Interupt is unmasked in MSS_PERIPH_ERRAGG_MASK0Wrie 0x1 to clear this interrupt.
  [8] MSS_PERIPH_ERRAGG_STATUS0_HSM_SOC_CTRL_RD — Status of Interrupt from HSM_SOC_CTRLSet only if Interupt is unmasked in MSS_PERIPH_ERRAGG_MASK0Wrie 0x1 to clear this interrupt.
  [7] MSS_PERIPH_ERRAGG_STATUS0_TOP_RCM_WR — Status of Interrupt from TOP_RCMSet only if Interupt is unmasked in MSS_PERIPH_ERRAGG_MASK0Wrie 0x1 to clear this interrupt.
  [6] MSS_PERIPH_ERRAGG_STATUS0_TOP_RCM_RD — Status of Interrupt from TOP_RCMSet only if Interupt is unmasked in MSS_PERIPH_ERRAGG_MASK0Wrie 0x1 to clear this interrupt.
  [5] MSS_PERIPH_ERRAGG_STATUS0_TOP_CTRL_WR — Status of Interrupt from TOP_CTRLSet only if Interupt is unmasked in MSS_PERIPH_ERRAGG_MASK0Wrie 0x1 to clear this interrupt.
  [4] MSS_PERIPH_ERRAGG_STATUS0_TOP_CTRL_RD — Status of Interrupt from TOP_CTRLSet only if Interupt is unmasked in MSS_PERIPH_ERRAGG_MASK0Wrie 0x1 to clear this interrupt.
  [3] MSS_PERIPH_ERRAGG_STATUS0_MSS_RCM_WR — Status of Interrupt from MSS_RCMSet only if Interupt is unmasked in MSS_PERIPH_ERRAGG_MASK0Wrie 0x1 to clear this interrupt.
  [2] MSS_PERIPH_ERRAGG_STATUS0_MSS_RCM_RD — Status of Interrupt from MSS_RCMSet only if Interupt is unmasked in MSS_PERIPH_ERRAGG_MASK0Wrie 0x1 to clear this interrupt.
  [1] MSS_PERIPH_ERRAGG_STATUS0_MSS_CTRL_WR — Status of Interrupt from MSS_CTRLSet only if Interupt is unmasked in MSS_PERIPH_ERRAGG_MASK0Wrie 0x1 to clear this interrupt.
  [0] MSS_PERIPH_ERRAGG_STATUS0_MSS_CTRL_RD — Status of Interrupt from MSS_CTRLSet only if Interupt is unmasked in MSS_PERIPH_ERRAGG_MASK0Wrie 0x1 to clear this interrupt.
0x18018 MSS_CTRL_MSS_PERIPH_ERRAGG_STATUS_RAW0 rw — This register shows the Status of all MMR Access Errors.
  [11] MSS_PERIPH_ERRAGG_STATUS_RAW0_HSM_CTRL_WR — Raw Status of Interrupt from HSM_CTRL. Set irrespective if the Interupt is masked or unmasked in MSS_PERIPH_ERRAGG_MASK0
  [10] MSS_PERIPH_ERRAGG_STATUS_RAW0_HSM_CTRL_RD — Raw Status of Interrupt from HSM_CTRL. Set irrespective if the Interupt is masked or unmasked in MSS_PERIPH_ERRAGG_MASK0
  [9] MSS_PERIPH_ERRAGG_STATUS_RAW0_HSM_SOC_CTRL_WR — Raw Status of Interrupt from HSM_SOC_CTRL. Set irrespective if the Interupt is masked or unmasked in MSS_PERIPH_ERRAGG_MASK0
  [8] MSS_PERIPH_ERRAGG_STATUS_RAW0_HSM_SOC_CTRL_RD — Raw Status of Interrupt from HSM_SOC_CTRL. Set irrespective if the Interupt is masked or unmasked in MSS_PERIPH_ERRAGG_MASK0
  [7] MSS_PERIPH_ERRAGG_STATUS_RAW0_TOP_RCM_WR — Raw Status of Interrupt from TOP_RCM. Set irrespective if the Interupt is masked or unmasked in MSS_PERIPH_ERRAGG_MASK0
  [6] MSS_PERIPH_ERRAGG_STATUS_RAW0_TOP_RCM_RD — Raw Status of Interrupt from TOP_RCM. Set irrespective if the Interupt is masked or unmasked in MSS_PERIPH_ERRAGG_MASK0
  [5] MSS_PERIPH_ERRAGG_STATUS_RAW0_TOP_CTRL_WR — Raw Status of Interrupt from TOP_CTRL. Set irrespective if the Interupt is masked or unmasked in MSS_PERIPH_ERRAGG_MASK0
  [4] MSS_PERIPH_ERRAGG_STATUS_RAW0_TOP_CTRL_RD — Raw Status of Interrupt from TOP_CTRL. Set irrespective if the Interupt is masked or unmasked in MSS_PERIPH_ERRAGG_MASK0
  [3] MSS_PERIPH_ERRAGG_STATUS_RAW0_MSS_RCM_WR — Raw Status of Interrupt from MSS_RCM. Set irrespective if the Interupt is masked or unmasked in MSS_PERIPH_ERRAGG_MASK0
  [2] MSS_PERIPH_ERRAGG_STATUS_RAW0_MSS_RCM_RD — Raw Status of Interrupt from MSS_RCM. Set irrespective if the Interupt is masked or unmasked in MSS_PERIPH_ERRAGG_MASK0
  [1] MSS_PERIPH_ERRAGG_STATUS_RAW0_MSS_CTRL_WR — Raw Status of Interrupt from MSS_CTRL. Set irrespective if the Interupt is masked or unmasked in MSS_PERIPH_ERRAGG_MASK0
  [0] MSS_PERIPH_ERRAGG_STATUS_RAW0_MSS_CTRL_RD — Raw Status of Interrupt from MSS_CTRL. Set irrespective if the Interupt is masked or unmasked in MSS_PERIPH_ERRAGG_MASK0
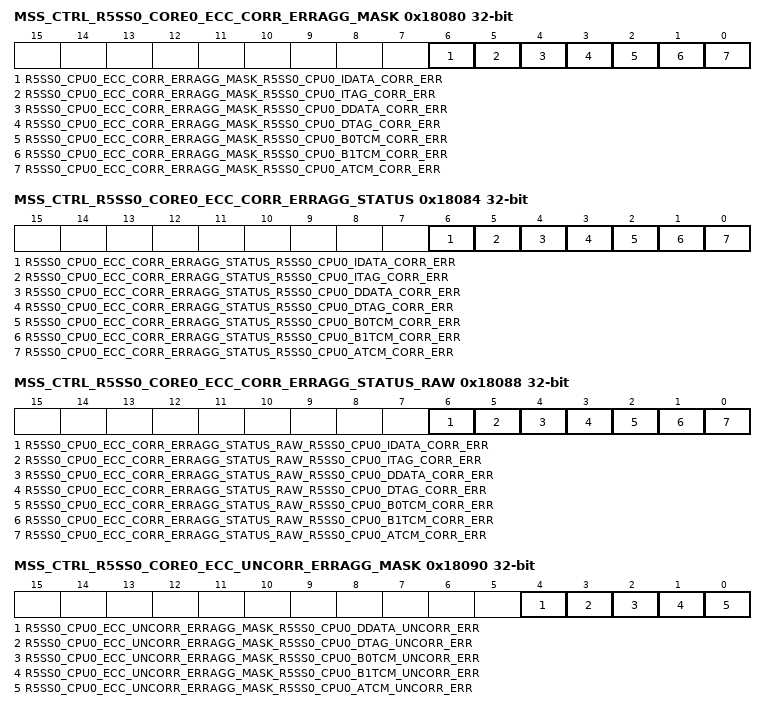
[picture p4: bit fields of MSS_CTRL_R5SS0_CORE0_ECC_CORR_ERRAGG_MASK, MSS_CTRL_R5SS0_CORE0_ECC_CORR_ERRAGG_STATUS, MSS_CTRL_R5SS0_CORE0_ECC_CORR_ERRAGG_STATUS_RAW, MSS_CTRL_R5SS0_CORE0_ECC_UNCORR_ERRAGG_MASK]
0x18080 MSS_CTRL_R5SS0_CORE0_ECC_CORR_ERRAGG_MASK rw — Register to Mask Correctable error from R5SS0 CORE0 Memories.
  [6] R5SS0_CPU0_ECC_CORR_ERRAGG_MASK_R5SS0_CPU0_IDATA_CORR_ERR — Mask Interrupt for correctable errors to aggregated Interrupt of corresponding CPU1'b1 : Interrupt is Masked1'b0 : Interrupt is Unmasked
  [5] R5SS0_CPU0_ECC_CORR_ERRAGG_MASK_R5SS0_CPU0_ITAG_CORR_ERR — Mask Interrupt for correctable errors to aggregated Interrupt of corresponding CPU1'b1 : Interrupt is Masked1'b0 : Interrupt is Unmasked
  [4] R5SS0_CPU0_ECC_CORR_ERRAGG_MASK_R5SS0_CPU0_DDATA_CORR_ERR — Mask Interrupt for correctable errors to aggregated Interrupt of corresponding CPU1'b1 : Interrupt is Masked1'b0 : Interrupt is Unmasked
  [3] R5SS0_CPU0_ECC_CORR_ERRAGG_MASK_R5SS0_CPU0_DTAG_CORR_ERR — Mask Interrupt for correctable errors to aggregated Interrupt of corresponding CPU1'b1 : Interrupt is Masked1'b0 : Interrupt is Unmasked
  [2] R5SS0_CPU0_ECC_CORR_ERRAGG_MASK_R5SS0_CPU0_B0TCM_CORR_ERR — Mask Interrupt for correctable errors to aggregated Interrupt of corresponding CPU1'b1 : Interrupt is Masked1'b0 : Interrupt is Unmasked
  [1] R5SS0_CPU0_ECC_CORR_ERRAGG_MASK_R5SS0_CPU0_B1TCM_CORR_ERR — Mask Interrupt for correctable errors to aggregated Interrupt of corresponding CPU1'b1 : Interrupt is Masked1'b0 : Interrupt is Unmasked
  [0] R5SS0_CPU0_ECC_CORR_ERRAGG_MASK_R5SS0_CPU0_ATCM_CORR_ERR — Mask Interrupt for correctable errors to aggregated Interrupt of corresponding CPU1'b1 : Interrupt is Masked1'b0 : Interrupt is Unmasked
0x18084 MSS_CTRL_R5SS0_CORE0_ECC_CORR_ERRAGG_STATUS rw — Status register based on mask for correctable error R5SS0 CORE0 Memories.
  [6] R5SS0_CPU0_ECC_CORR_ERRAGG_STATUS_R5SS0_CPU0_IDATA_CORR_ERR — Status of Interrupt from correctable error of corresponding CPUSet only if Interupt is unmasked in corresponding R5SS*_CPU*_ECC_CORR_ERRAGG_MASK registerWrie 0x1 to clear this interrupt.
  [5] R5SS0_CPU0_ECC_CORR_ERRAGG_STATUS_R5SS0_CPU0_ITAG_CORR_ERR — Status of Interrupt from correctable error of corresponding CPUSet only if Interupt is unmasked in corresponding R5SS*_CPU*_ECC_CORR_ERRAGG_MASK registerWrie 0x1 to clear this interrupt.
  [4] R5SS0_CPU0_ECC_CORR_ERRAGG_STATUS_R5SS0_CPU0_DDATA_CORR_ERR — Status of Interrupt from correctable error of corresponding CPUSet only if Interupt is unmasked in corresponding R5SS*_CPU*_ECC_CORR_ERRAGG_MASK registerWrie 0x1 to clear this interrupt.
  [3] R5SS0_CPU0_ECC_CORR_ERRAGG_STATUS_R5SS0_CPU0_DTAG_CORR_ERR — Status of Interrupt from correctable error of corresponding CPUSet only if Interupt is unmasked in corresponding R5SS*_CPU*_ECC_CORR_ERRAGG_MASK registerWrie 0x1 to clear this interrupt.
  [2] R5SS0_CPU0_ECC_CORR_ERRAGG_STATUS_R5SS0_CPU0_B0TCM_CORR_ERR — Status of Interrupt from correctable error of corresponding CPUSet only if Interupt is unmasked in corresponding R5SS*_CPU*_ECC_CORR_ERRAGG_MASK registerWrie 0x1 to clear this interrupt.
  [1] R5SS0_CPU0_ECC_CORR_ERRAGG_STATUS_R5SS0_CPU0_B1TCM_CORR_ERR — Status of Interrupt from correctable error of corresponding CPUSet only if Interupt is unmasked in corresponding R5SS*_CPU*_ECC_CORR_ERRAGG_MASK registerWrie 0x1 to clear this interrupt.
  [0] R5SS0_CPU0_ECC_CORR_ERRAGG_STATUS_R5SS0_CPU0_ATCM_CORR_ERR — Status of Interrupt from correctable error of corresponding CPUSet only if Interupt is unmasked in corresponding R5SS*_CPU*_ECC_CORR_ERRAGG_MASK registerWrie 0x1 to clear this interrupt.
0x18088 MSS_CTRL_R5SS0_CORE0_ECC_CORR_ERRAGG_STATUS_RAW rw — Raw status for correctable error from R5SS0 CORE0 Memories.
  [6] R5SS0_CPU0_ECC_CORR_ERRAGG_STATUS_RAW_R5SS0_CPU0_IDATA_CORR_ERR — Raw Status of Interrupt from correctable error of corresponding CPUSet only if Interupt is unmasked in corresponding R5SS*_CPU*_ECC_CORR_ERRAGG_MASK registerWrie 0x1 to clear this interrupt.
  [5] R5SS0_CPU0_ECC_CORR_ERRAGG_STATUS_RAW_R5SS0_CPU0_ITAG_CORR_ERR — Raw Status of Interrupt from correctable error of corresponding CPUSet only if Interupt is unmasked in corresponding R5SS*_CPU*_ECC_CORR_ERRAGG_MASK registerWrie 0x1 to clear this interrupt.
  [4] R5SS0_CPU0_ECC_CORR_ERRAGG_STATUS_RAW_R5SS0_CPU0_DDATA_CORR_ERR — Raw Status of Interrupt from correctable error of corresponding CPUSet only if Interupt is unmasked in corresponding R5SS*_CPU*_ECC_CORR_ERRAGG_MASK registerWrie 0x1 to clear this interrupt.
  [3] R5SS0_CPU0_ECC_CORR_ERRAGG_STATUS_RAW_R5SS0_CPU0_DTAG_CORR_ERR — Raw Status of Interrupt from correctable error of corresponding CPUSet only if Interupt is unmasked in corresponding R5SS*_CPU*_ECC_CORR_ERRAGG_MASK registerWrie 0x1 to clear this interrupt.
  [2] R5SS0_CPU0_ECC_CORR_ERRAGG_STATUS_RAW_R5SS0_CPU0_B0TCM_CORR_ERR — Raw Status of Interrupt from correctable error of corresponding CPUSet only if Interupt is unmasked in corresponding R5SS*_CPU*_ECC_CORR_ERRAGG_MASK registerWrie 0x1 to clear this interrupt.
  [1] R5SS0_CPU0_ECC_CORR_ERRAGG_STATUS_RAW_R5SS0_CPU0_B1TCM_CORR_ERR — Raw Status of Interrupt from correctable error of corresponding CPUSet only if Interupt is unmasked in corresponding R5SS*_CPU*_ECC_CORR_ERRAGG_MASK registerWrie 0x1 to clear this interrupt.
  [0] R5SS0_CPU0_ECC_CORR_ERRAGG_STATUS_RAW_R5SS0_CPU0_ATCM_CORR_ERR — Raw Status of Interrupt from correctable error of corresponding CPUSet only if Interupt is unmasked in corresponding R5SS*_CPU*_ECC_CORR_ERRAGG_MASK registerWrie 0x1 to clear this interrupt.
0x18090 MSS_CTRL_R5SS0_CORE0_ECC_UNCORR_ERRAGG_MASK rw — Register to Mask Uncorrectable error from R5SS0 CORE0 Memories.
  [4] R5SS0_CPU0_ECC_UNCORR_ERRAGG_MASK_R5SS0_CPU0_DDATA_UNCORR_ERR — Mask Interrupt for correctable errors to aggregated Interrupt of corresponding CPU1'b1 : Interrupt is Masked1'b0 : Interrupt is Unmasked
  [3] R5SS0_CPU0_ECC_UNCORR_ERRAGG_MASK_R5SS0_CPU0_DTAG_UNCORR_ERR — Mask Interrupt for correctable errors to aggregated Interrupt of corresponding CPU1'b1 : Interrupt is Masked1'b0 : Interrupt is Unmasked
  [2] R5SS0_CPU0_ECC_UNCORR_ERRAGG_MASK_R5SS0_CPU0_B0TCM_UNCORR_ERR — Mask Interrupt for correctable errors to aggregated Interrupt of corresponding CPU1'b1 : Interrupt is Masked1'b0 : Interrupt is Unmasked
  [1] R5SS0_CPU0_ECC_UNCORR_ERRAGG_MASK_R5SS0_CPU0_B1TCM_UNCORR_ERR — Mask Interrupt for correctable errors to aggregated Interrupt of corresponding CPU1'b1 : Interrupt is Masked1'b0 : Interrupt is Unmasked
  [0] R5SS0_CPU0_ECC_UNCORR_ERRAGG_MASK_R5SS0_CPU0_ATCM_UNCORR_ERR — Mask Interrupt for correctable errors to aggregated Interrupt of corresponding CPU1'b1 : Interrupt is Masked1'b0 : Interrupt is Unmasked
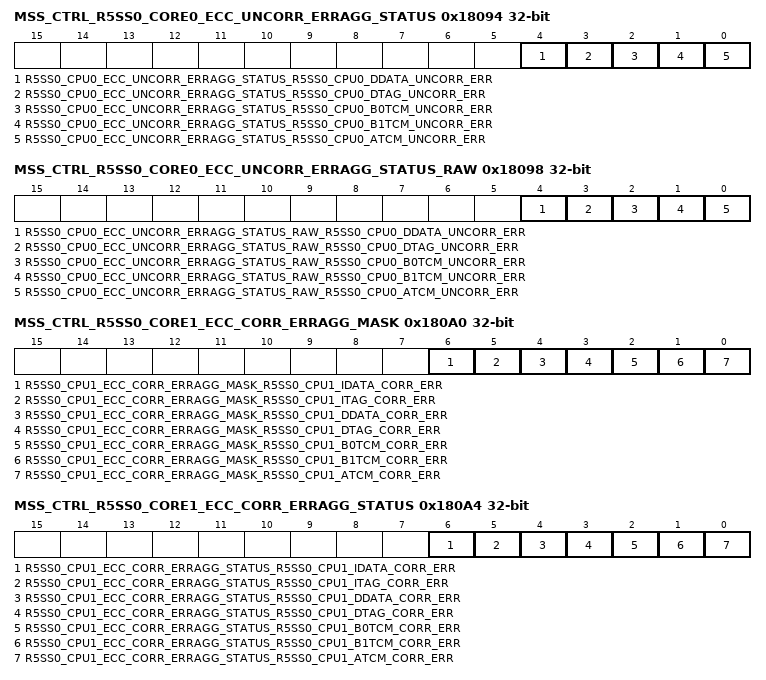
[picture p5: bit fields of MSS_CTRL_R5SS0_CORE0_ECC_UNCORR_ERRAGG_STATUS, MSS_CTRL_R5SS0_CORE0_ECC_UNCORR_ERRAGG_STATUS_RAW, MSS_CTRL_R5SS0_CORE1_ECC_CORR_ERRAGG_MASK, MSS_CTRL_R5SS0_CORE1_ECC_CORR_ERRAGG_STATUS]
0x18094 MSS_CTRL_R5SS0_CORE0_ECC_UNCORR_ERRAGG_STATUS rw — Status register based on mask for uncorrectable error R5SS0 CORE0 Memories.
  [4] R5SS0_CPU0_ECC_UNCORR_ERRAGG_STATUS_R5SS0_CPU0_DDATA_UNCORR_ERR — Status of Interrupt from correctable error of corresponding CPUSet only if Interupt is unmasked in corresponding R5SS*_CPU*_ECC_UNCORR_ERRAGG_MASK registerWrie 0x1 to clear this interrupt.
  [3] R5SS0_CPU0_ECC_UNCORR_ERRAGG_STATUS_R5SS0_CPU0_DTAG_UNCORR_ERR — Status of Interrupt from correctable error of corresponding CPUSet only if Interupt is unmasked in corresponding R5SS*_CPU*_ECC_UNCORR_ERRAGG_MASK registerWrie 0x1 to clear this interrupt.
  [2] R5SS0_CPU0_ECC_UNCORR_ERRAGG_STATUS_R5SS0_CPU0_B0TCM_UNCORR_ERR — Status of Interrupt from correctable error of corresponding CPUSet only if Interupt is unmasked in corresponding R5SS*_CPU*_ECC_UNCORR_ERRAGG_MASK registerWrie 0x1 to clear this interrupt.
  [1] R5SS0_CPU0_ECC_UNCORR_ERRAGG_STATUS_R5SS0_CPU0_B1TCM_UNCORR_ERR — Status of Interrupt from correctable error of corresponding CPUSet only if Interupt is unmasked in corresponding R5SS*_CPU*_ECC_UNCORR_ERRAGG_MASK registerWrie 0x1 to clear this interrupt.
  [0] R5SS0_CPU0_ECC_UNCORR_ERRAGG_STATUS_R5SS0_CPU0_ATCM_UNCORR_ERR — Status of Interrupt from correctable error of corresponding CPUSet only if Interupt is unmasked in corresponding R5SS*_CPU*_ECC_UNCORR_ERRAGG_MASK registerWrie 0x1 to clear this interrupt.
0x18098 MSS_CTRL_R5SS0_CORE0_ECC_UNCORR_ERRAGG_STATUS_RAW rw — Raw status for uncorrectable error from R5SS0 CORE0 Memories.
  [4] R5SS0_CPU0_ECC_UNCORR_ERRAGG_STATUS_RAW_R5SS0_CPU0_DDATA_UNCORR_ERR — Raw Status of Interrupt from correctable error of corresponding CPUSet only if Interupt is unmasked in corresponding R5SS*_CPU*_ECC_UNCORR_ERRAGG_MASK registerWrie 0x1 to clear this interrupt.
  [3] R5SS0_CPU0_ECC_UNCORR_ERRAGG_STATUS_RAW_R5SS0_CPU0_DTAG_UNCORR_ERR — Raw Status of Interrupt from correctable error of corresponding CPUSet only if Interupt is unmasked in corresponding R5SS*_CPU*_ECC_UNCORR_ERRAGG_MASK registerWrie 0x1 to clear this interrupt.
  [2] R5SS0_CPU0_ECC_UNCORR_ERRAGG_STATUS_RAW_R5SS0_CPU0_B0TCM_UNCORR_ERR — Raw Status of Interrupt from correctable error of corresponding CPUSet only if Interupt is unmasked in corresponding R5SS*_CPU*_ECC_UNCORR_ERRAGG_MASK registerWrie 0x1 to clear this interrupt.
  [1] R5SS0_CPU0_ECC_UNCORR_ERRAGG_STATUS_RAW_R5SS0_CPU0_B1TCM_UNCORR_ERR — Raw Status of Interrupt from correctable error of corresponding CPUSet only if Interupt is unmasked in corresponding R5SS*_CPU*_ECC_UNCORR_ERRAGG_MASK registerWrie 0x1 to clear this interrupt.
  [0] R5SS0_CPU0_ECC_UNCORR_ERRAGG_STATUS_RAW_R5SS0_CPU0_ATCM_UNCORR_ERR — Raw Status of Interrupt from correctable error of corresponding CPUSet only if Interupt is unmasked in corresponding R5SS*_CPU*_ECC_UNCORR_ERRAGG_MASK registerWrie 0x1 to clear this interrupt.
0x180A0 MSS_CTRL_R5SS0_CORE1_ECC_CORR_ERRAGG_MASK rw — Register to Mask Correctable error from R5SS0 CORE1 Memories.
  [6] R5SS0_CPU1_ECC_CORR_ERRAGG_MASK_R5SS0_CPU1_IDATA_CORR_ERR — Mask Interrupt for correctable errors to aggregated Interrupt of corresponding CPU1'b1 : Interrupt is Masked1'b0 : Interrupt is Unmasked
  [5] R5SS0_CPU1_ECC_CORR_ERRAGG_MASK_R5SS0_CPU1_ITAG_CORR_ERR — Mask Interrupt for correctable errors to aggregated Interrupt of corresponding CPU1'b1 : Interrupt is Masked1'b0 : Interrupt is Unmasked
  [4] R5SS0_CPU1_ECC_CORR_ERRAGG_MASK_R5SS0_CPU1_DDATA_CORR_ERR — Mask Interrupt for correctable errors to aggregated Interrupt of corresponding CPU1'b1 : Interrupt is Masked1'b0 : Interrupt is Unmasked
  [3] R5SS0_CPU1_ECC_CORR_ERRAGG_MASK_R5SS0_CPU1_DTAG_CORR_ERR — Mask Interrupt for correctable errors to aggregated Interrupt of corresponding CPU1'b1 : Interrupt is Masked1'b0 : Interrupt is Unmasked
  [2] R5SS0_CPU1_ECC_CORR_ERRAGG_MASK_R5SS0_CPU1_B0TCM_CORR_ERR — Mask Interrupt for correctable errors to aggregated Interrupt of corresponding CPU1'b1 : Interrupt is Masked1'b0 : Interrupt is Unmasked
  [1] R5SS0_CPU1_ECC_CORR_ERRAGG_MASK_R5SS0_CPU1_B1TCM_CORR_ERR — Mask Interrupt for correctable errors to aggregated Interrupt of corresponding CPU1'b1 : Interrupt is Masked1'b0 : Interrupt is Unmasked
  [0] R5SS0_CPU1_ECC_CORR_ERRAGG_MASK_R5SS0_CPU1_ATCM_CORR_ERR — Mask Interrupt for correctable errors to aggregated Interrupt of corresponding CPU1'b1 : Interrupt is Masked1'b0 : Interrupt is Unmasked
0x180A4 MSS_CTRL_R5SS0_CORE1_ECC_CORR_ERRAGG_STATUS rw — Status register based on mask for correctable error R5SS0 CORE1 Memories.
  [6] R5SS0_CPU1_ECC_CORR_ERRAGG_STATUS_R5SS0_CPU1_IDATA_CORR_ERR — Status of Interrupt from correctable error of corresponding CPUSet only if Interupt is unmasked in corresponding R5SS*_CPU*_ECC_CORR_ERRAGG_MASK registerWrie 0x1 to clear this interrupt.
  [5] R5SS0_CPU1_ECC_CORR_ERRAGG_STATUS_R5SS0_CPU1_ITAG_CORR_ERR — Status of Interrupt from correctable error of corresponding CPUSet only if Interupt is unmasked in corresponding R5SS*_CPU*_ECC_CORR_ERRAGG_MASK registerWrie 0x1 to clear this interrupt.
  [4] R5SS0_CPU1_ECC_CORR_ERRAGG_STATUS_R5SS0_CPU1_DDATA_CORR_ERR — Status of Interrupt from correctable error of corresponding CPUSet only if Interupt is unmasked in corresponding R5SS*_CPU*_ECC_CORR_ERRAGG_MASK registerWrie 0x1 to clear this interrupt.
  [3] R5SS0_CPU1_ECC_CORR_ERRAGG_STATUS_R5SS0_CPU1_DTAG_CORR_ERR — Status of Interrupt from correctable error of corresponding CPUSet only if Interupt is unmasked in corresponding R5SS*_CPU*_ECC_CORR_ERRAGG_MASK registerWrie 0x1 to clear this interrupt.
  [2] R5SS0_CPU1_ECC_CORR_ERRAGG_STATUS_R5SS0_CPU1_B0TCM_CORR_ERR — Status of Interrupt from correctable error of corresponding CPUSet only if Interupt is unmasked in corresponding R5SS*_CPU*_ECC_CORR_ERRAGG_MASK registerWrie 0x1 to clear this interrupt.
  [1] R5SS0_CPU1_ECC_CORR_ERRAGG_STATUS_R5SS0_CPU1_B1TCM_CORR_ERR — Status of Interrupt from correctable error of corresponding CPUSet only if Interupt is unmasked in corresponding R5SS*_CPU*_ECC_CORR_ERRAGG_MASK registerWrie 0x1 to clear this interrupt.
  [0] R5SS0_CPU1_ECC_CORR_ERRAGG_STATUS_R5SS0_CPU1_ATCM_CORR_ERR — Status of Interrupt from correctable error of corresponding CPUSet only if Interupt is unmasked in corresponding R5SS*_CPU*_ECC_CORR_ERRAGG_MASK registerWrie 0x1 to clear this interrupt.
